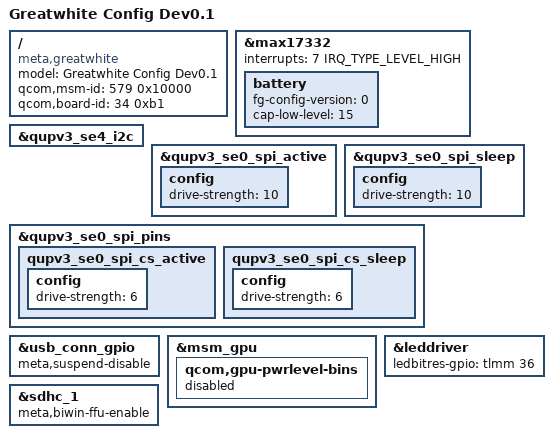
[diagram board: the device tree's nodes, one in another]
/dts-v1/;
/plugin/;

#include "greatwhite.dtsi"

/ {
	model = "Greatwhite Config Dev0.1";
	compatible = "meta,greatwhite", "meta,greatwhite-dev0.1";
	qcom,msm-id = <579 0x10000>;
	qcom,board-id = <34 0xb1>;
};

&max17332 {
	interrupts = <7 IRQ_TYPE_LEVEL_HIGH>;
	battery {
		/* disable FG update */
		fg-config-version   = /bits/ 8 <0>;
		cap-low-level		= /bits/ 8 <15>;
	};
};

/* Display card (Celeste) I2C bus: */

&qupv3_se4_i2c {
	status = "ok";
};


&qupv3_se0_spi_active {
	config {
		drive-strength = <10>;
	};
};

&qupv3_se0_spi_sleep {
	config {
		drive-strength = <10>;
	};
};

&qupv3_se0_spi_pins {
	qupv3_se0_spi_cs_active {
		config {
			drive-strength = <6>;
		};
	};

	qupv3_se0_spi_cs_sleep {
		config {
			drive-strength = <6>;
		};
	};
};

&usb_conn_gpio {
	meta,suspend-disable;
};

&msm_gpu {
	qcom,gpu-pwrlevel-bins {
		status = "disabled";
	};
};

&leddriver {
	ledbitres-gpio = <&tlmm 36 GPIO_ACTIVE_HIGH>;
};

&sdhc_1 {
        meta,biwin-ffu-enable;
};

#include "meta-neo-action-button.dtsi"
#include "greatwhite-hyperoff-rt500.dtsi"
